# ATmega16U2 register map
Vendor: Atmel; File version: 1.0
CPU: other r0p0, little endian, no MPU, no FPU, 4 interrupt priority bits
Registers are 8-bit, read-write, reset 0x0 unless marked. A register's access mark holds for its fields unless they carry their own. Offsets are from the block's base; [hi:lo] are bit positions.

## TC0 — Timer/Counter, 8-bit
Base 0x00000035
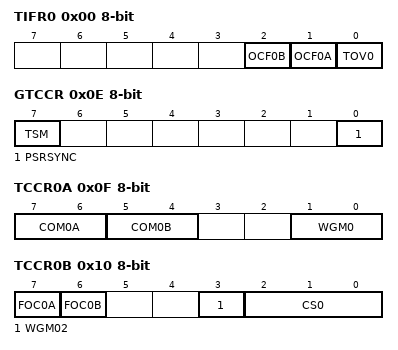
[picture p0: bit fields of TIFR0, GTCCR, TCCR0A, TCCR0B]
0x00 TIFR0 — Timer/Counter0 Interrupt Flag register
  [2] OCF0B — Timer/Counter0 Output Compare Flag 0B
  [1] OCF0A — Timer/Counter0 Output Compare Flag 0A
  [0] TOV0 — Timer/Counter0 Overflow Flag
0x0E GTCCR — General Timer/Counter Control Register
  [7] TSM — Timer/Counter Synchronization Mode
  [0] PSRSYNC — Prescaler Reset Timer/Counter1 and Timer/Counter0
0x0F TCCR0A — Timer/Counter Control Register A
  [7:6] COM0A — Compare Output Mode, Phase Correct PWM Mode
  [5:4] COM0B — Compare Output Mode, Fast PWm
  [1:0] WGM0 — Waveform Generation Mode
0x10 TCCR0B — Timer/Counter Control Register B
  [7] FOC0A — Force Output Compare A
  [6] FOC0B — Force Output Compare B
  [3] WGM02
  [2:0] CS0 — Clock Select
    0=NO_CLOCK_SOURCE_STOPPED; 1=RUNNING_NO_PRESCALING; 2=RUNNING_CLK_8; 3=RUNNING_CLK_64; 4=RUNNING_CLK_256; 5=RUNNING_CLK_1024; 6=RUNNING_EXTCLK_TN_FALLING_EDGE; 7=RUNNING_EXTCLK_TN_RISING_EDGE
0x11 TCNT0 — Timer/Counter0
  [7:0] TCNT0 — Timer/Counter0 bits
0x12 OCR0A — Timer/Counter0 Output Compare Register
  [7:0] OCR0A — Timer/Counter0 Output Compare A bits
0x13 OCR0B — Timer/Counter0 Output Compare Register
  [7:0] OCR0B — Timer/Counter0 Output Compare B bits
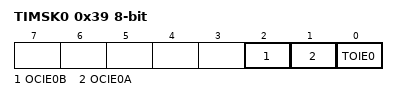
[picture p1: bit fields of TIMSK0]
0x39 TIMSK0 — Timer/Counter0 Interrupt Mask Register
  [2] OCIE0B — Timer/Counter0 Output Compare Match B Interrupt Enable
  [1] OCIE0A — Timer/Counter0 Output Compare Match A Interrupt Enable
  [0] TOIE0 — Timer/Counter0 Overflow Interrupt Enable

## TC1 — Timer/Counter, 16-bit
Base 0x00000036
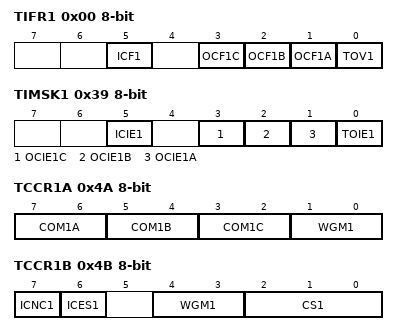
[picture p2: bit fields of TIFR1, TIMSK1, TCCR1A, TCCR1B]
0x00 TIFR1 — Timer/Counter1 Interrupt Flag register
  [5] ICF1 — Input Capture Flag 1
  [3] OCF1C — Output Compare Flag 1C
  [2] OCF1B — Output Compare Flag 1B
  [1] OCF1A — Output Compare Flag 1A
  [0] TOV1 — Timer/Counter1 Overflow Flag
0x39 TIMSK1 — Timer/Counter1 Interrupt Mask Register
  [5] ICIE1 — Timer/Counter1 Input Capture Interrupt Enable
  [3] OCIE1C — Timer/Counter1 Output Compare C Match Interrupt Enable
  [2] OCIE1B — Timer/Counter1 Output Compare B Match Interrupt Enable
  [1] OCIE1A — Timer/Counter1 Output Compare A Match Interrupt Enable
  [0] TOIE1 — Timer/Counter1 Overflow Interrupt Enable
0x4A TCCR1A — Timer/Counter1 Control Register A
  [7:6] COM1A — Compare Output Mode 1A, bits
  [5:4] COM1B — Compare Output Mode 1B, bits
  [3:2] COM1C — Compare Output Mode 1C, bits
  [1:0] WGM1 — Waveform Generation Mode
0x4B TCCR1B — Timer/Counter1 Control Register B
  [7] ICNC1 — Input Capture 1 Noise Canceler
  [6] ICES1 — Input Capture 1 Edge Select
  [4:3] WGM1 — Waveform Generation Mode
  [2:0] CS1 — Prescaler source of Timer/Counter 1
    0=NO_CLOCK_SOURCE_STOPPED; 1=RUNNING_NO_PRESCALING; 2=RUNNING_CLK_8; 3=RUNNING_CLK_64; 4=RUNNING_CLK_256; 5=RUNNING_CLK_1024; 6=RUNNING_EXTCLK_TN_FALLING_EDGE; 7=RUNNING_EXTCLK_TN_RISING_EDGE
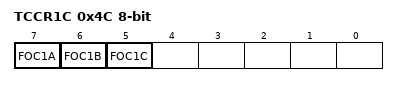
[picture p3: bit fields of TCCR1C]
0x4C TCCR1C — Timer/Counter 1 Control Register C
  [7] FOC1A — Force Output Compare 1A
  [6] FOC1B — Force Output Compare 1B
  [5] FOC1C — Force Output Compare 1C
0x4E TCNT1 16-bit (reset mask 0xFF) — Timer/Counter1 Bytes
  [15:0] TCNT1 — Timer/Counter1 bits
0x50 ICR1 16-bit (reset mask 0xFF) — Timer/Counter1 Input Capture Register Bytes
  [15:0] ICR1 — Timer/Counter1 Input Capture bits
0x52 OCR1A 16-bit (reset mask 0xFF) — Timer/Counter1 Output Compare Register A Bytes
  [15:0] OCR1A — Timer/Counter1 Output Compare A bits
0x54 OCR1B 16-bit (reset mask 0xFF) — Timer/Counter1 Output Compare Register B Bytes
  [15:0] OCR1B — Timer/Counter1 Output Compare B bits
0x56 OCR1C 16-bit (reset mask 0xFF) — Timer/Counter1 Output Compare Register C Bytes
  [15:0] OCR1C — Timer/Counter1 Output Compare C bits

## USART1 — USART
Base 0x000000C8
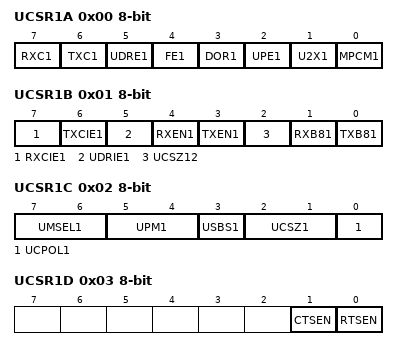
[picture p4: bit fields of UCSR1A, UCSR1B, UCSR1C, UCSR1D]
0x00 UCSR1A — USART Control and Status Register A
  [7] RXC1 — USART Receive Complete
  [6] TXC1 — USART Transmit Complete
  [5] UDRE1 — USART Data Register Empty
  [4] FE1 — Framing Error
  [3] DOR1 — Data overRun
  [2] UPE1 — Parity Error
  [1] U2X1 — Double the USART transmission speed
  [0] MPCM1 — Multi-processor Communication Mode
0x01 UCSR1B — USART Control and Status Register B
  [7] RXCIE1 — RX Complete Interrupt Enable
  [6] TXCIE1 — TX Complete Interrupt Enable
  [5] UDRIE1 — USART Data register Empty Interrupt Enable
  [4] RXEN1 — Receiver Enable
  [3] TXEN1 — Transmitter Enable
  [2] UCSZ12 — Character Size
  [1] RXB81 — Receive Data Bit 8
  [0] TXB81 — Transmit Data Bit 8
0x02 UCSR1C — USART Control and Status Register C
  [7:6] UMSEL1 — USART Mode Select
  [5:4] UPM1 — Parity Mode Bits
  [3] USBS1 — Stop Bit Select
  [2:1] UCSZ1 — Character Size
  [0] UCPOL1 — Clock Polarity
0x03 UCSR1D — USART Control and Status Register D
  [1] CTSEN — CTS Enable
  [0] RTSEN — RTS Enable
0x04 UBRR1 16-bit (reset mask 0xFF) — USART Baud Rate Register Bytes
  [11:0] UBRR1 — USART Baud Rate bits
0x06 UDR1 — USART I/O Data Register
  [7:0] UDR1 — USART I/O Data bits
